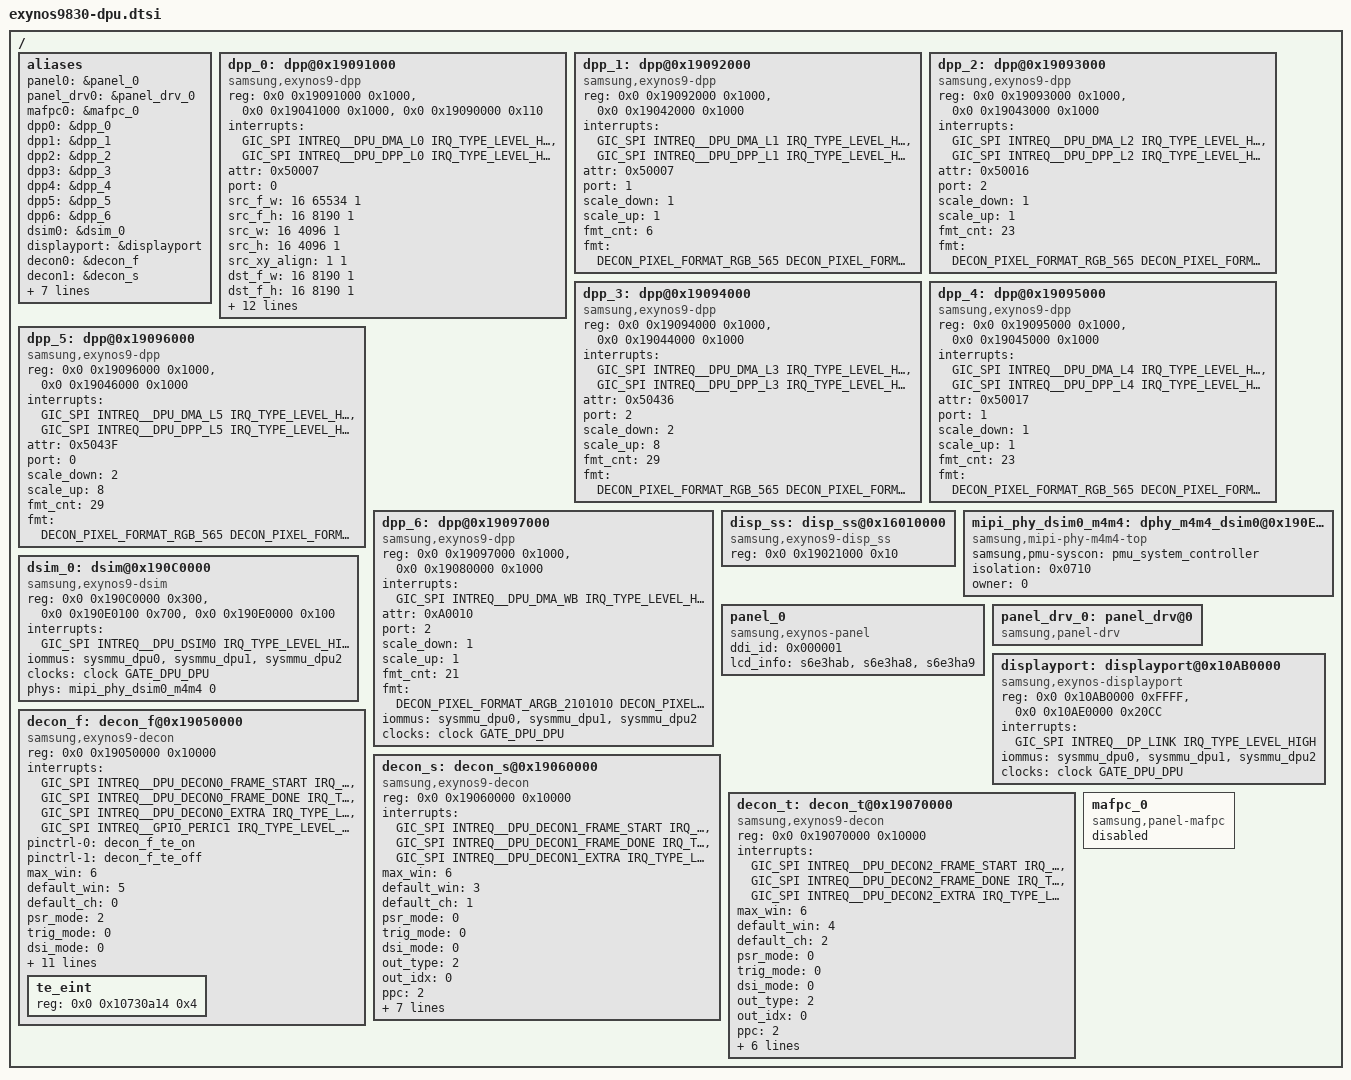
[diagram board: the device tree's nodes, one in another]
/*
 * SAMSUNG EXYNOS9830 SoC device tree source
 *
 * Copyright (c) 2014 Samsung Electronics Co., Ltd.
 *		http://www.samsung.com
 *
 * SAMSUNG EXYNOS9830 SoC device nodes are listed in this file.
 * EXYNOS based board files can include this file and provide
 * values for board specfic bindings.
 *
 * This program is free software; you can redistribute it and/or modify
 * it under the terms of the GNU General Public License version 2 as
 * published by the Free Software Foundation.
 */

#include <dt-bindings/interrupt-controller/arm-gic.h>
#include <dt-bindings/interrupt-controller/exynos9830.h>
#include <dt-bindings/display/exynos-display.h>
#include <dt-bindings/clock/exynos9830.h>
#include "exynos9830-display-lcd.dtsi"
#include "exynos9830-mcdhdr.dtsi"

/ {
	aliases {
		panel0 = &panel_0;
		panel_drv0 = &panel_drv_0;
       		mafpc0 = &mafpc_0;
		dpp0 = &dpp_0;
		dpp1 = &dpp_1;
		dpp2 = &dpp_2;
		dpp3 = &dpp_3;
		dpp4 = &dpp_4;
		dpp5 = &dpp_5;
		dpp6 = &dpp_6;
		dsim0 = &dsim_0;
		displayport = &displayport;
		decon0 = &decon_f;
		decon1 = &decon_s;
		decon2 = &decon_t;
		mcdhdr0 = &mcdhdr_0;
		mcdhdr1 = &mcdhdr_1;
		mcdhdr2 = &mcdhdr_2;
		mcdhdr3 = &mcdhdr_3;
		mcdhdr4 = &mcdhdr_4;
		mcdhdr5 = &mcdhdr_5;
	};

	dpp_0: dpp@0x19091000 {	/* GF0_L0 */
		compatible = "samsung,exynos9-dpp";
		#pb-id-cells = <3>;
		/* DPU_DMA, DPP, DPU_DMA_COMMON */
		reg = <0x0 0x19091000 0x1000>, <0x0 0x19041000 0x1000>, <0x0 0x19090000 0x110>;
		/* DPU_DMA IRQ, DPP IRQ */
		interrupts = <GIC_SPI INTREQ__DPU_DMA_L0 IRQ_TYPE_LEVEL_HIGH>,
			   <GIC_SPI INTREQ__DPU_DPP_L0 IRQ_TYPE_LEVEL_HIGH>;
		/* Each bit indicates DPP attribute */
		/* 0:AFBC 1:BLOCK 2:FLIP 3:ROT 4:CSC 5:SCALE 6:HDR 7:C_HDR 8:C_HDR10 9:WCG 10:SBWC */
		/* 16:IDMA 17:ODMA 18:DPP */
		/* DPP[18]/IDMA[16]/FLIP[2]/BLOCK[1]/AFBC[0] */
		attr = <0x50007>;
		port = <0>; /* AXI port number */

		/* HW restriction */
		src_f_w = <16 65534 1>;
		src_f_h = <16 8190 1>;
		src_w = <16 4096 1>;
		src_h = <16 4096 1>;
		src_xy_align = <1 1>;

		dst_f_w = <16 8190 1>;
		dst_f_h = <16 8190 1>;
		dst_w = <16 4096 1>;
		dst_h = <16 4096 1>;
		dst_xy_align = <1 1>;

		blk_w = <4 4096 1>;
		blk_h = <1 4096 1>;
		blk_xy_align = <1 1>;

		src_h_rot_max = <2160>;

		/* 1: scale X, 2: 1/2x scale down, 4: 1/4x scale down */
		scale_down = <1>;
		/* 1: scale X, 2: 2x scale up, 4: 4x scale up */
		scale_up = <1>;

		/* supported format count */
		fmt_cnt = <6>;
		/* supported format list */
		fmt = <DECON_PIXEL_FORMAT_RGB_565 DECON_PIXEL_FORMAT_BGR_565
			DECON_PIXEL_FORMAT_ARGB_2101010 DECON_PIXEL_FORMAT_ABGR_2101010
			DECON_PIXEL_FORMAT_RGBA_1010102 DECON_PIXEL_FORMAT_BGRA_1010102>;
	};

	dpp_1: dpp@0x19092000 {	/* GF1_L1 */
		compatible = "samsung,exynos9-dpp";
		#pb-id-cells = <3>;
		reg = <0x0 0x19092000 0x1000>, <0x0 0x19042000 0x1000>;
		interrupts = <GIC_SPI INTREQ__DPU_DMA_L1 IRQ_TYPE_LEVEL_HIGH>,
			   <GIC_SPI INTREQ__DPU_DPP_L1 IRQ_TYPE_LEVEL_HIGH>;
		/* DPP[18]/IDMA[16]/FLIP[2]/BLOCK[1]/AFBC[0] */
		attr = <0x50007>;
		port = <1>;
		scale_down = <1>;
		scale_up = <1>;
		fmt_cnt = <6>;
		fmt = <DECON_PIXEL_FORMAT_RGB_565 DECON_PIXEL_FORMAT_BGR_565
			DECON_PIXEL_FORMAT_ARGB_2101010 DECON_PIXEL_FORMAT_ABGR_2101010
			DECON_PIXEL_FORMAT_RGBA_1010102 DECON_PIXEL_FORMAT_BGRA_1010102>;
	};

	dpp_2: dpp@0x19093000 {	/* VG_L2 */
		compatible = "samsung,exynos9-dpp";
		#pb-id-cells = <3>;
		reg = <0x0 0x19093000 0x1000>, <0x0 0x19043000 0x1000>;
		interrupts = <GIC_SPI INTREQ__DPU_DMA_L2 IRQ_TYPE_LEVEL_HIGH>,
			   <GIC_SPI INTREQ__DPU_DPP_L2 IRQ_TYPE_LEVEL_HIGH>;
		/* DPP[18]/IDMA[16]/CSC[4]/FLIP[2]/BLOCK[1] */
		attr = <0x50016>;
		port = <2>;
		scale_down = <1>;
		scale_up = <1>;
		fmt_cnt = <23>;
		fmt = <DECON_PIXEL_FORMAT_RGB_565 DECON_PIXEL_FORMAT_BGR_565
			DECON_PIXEL_FORMAT_ARGB_2101010 DECON_PIXEL_FORMAT_ABGR_2101010
			DECON_PIXEL_FORMAT_RGBA_1010102 DECON_PIXEL_FORMAT_BGRA_1010102
			DECON_PIXEL_FORMAT_NV16 DECON_PIXEL_FORMAT_NV61
			DECON_PIXEL_FORMAT_NV12 DECON_PIXEL_FORMAT_NV21
			DECON_PIXEL_FORMAT_NV12M DECON_PIXEL_FORMAT_NV21M
			DECON_PIXEL_FORMAT_NV12N DECON_PIXEL_FORMAT_NV12N_10B
			DECON_PIXEL_FORMAT_NV12M_P010 DECON_PIXEL_FORMAT_NV21M_P010
			DECON_PIXEL_FORMAT_NV12M_S10B DECON_PIXEL_FORMAT_NV21M_S10B
			DECON_PIXEL_FORMAT_NV16M_P210 DECON_PIXEL_FORMAT_NV61M_P210
			DECON_PIXEL_FORMAT_NV16M_S10B DECON_PIXEL_FORMAT_NV61M_S10B
			DECON_PIXEL_FORMAT_NV12_P010>;
	};

	dpp_3: dpp@0x19094000 {	/* VGS_L3 */
		compatible = "samsung,exynos9-dpp";
		#pb-id-cells = <3>;
		reg = <0x0 0x19094000 0x1000>, <0x0 0x19044000 0x1000>;
		interrupts = <GIC_SPI INTREQ__DPU_DMA_L3 IRQ_TYPE_LEVEL_HIGH>,
			   <GIC_SPI INTREQ__DPU_DPP_L3 IRQ_TYPE_LEVEL_HIGH>;
		/* DPP[18]/IDMA[16]/SBWC[10]/SCALE[5]/CSC[4]/FLIP[2]/BLOCK[1] */
		attr = <0x50436>;
		port = <2>;
		scale_down = <2>;
		scale_up = <8>;
		fmt_cnt = <29>;
		fmt = <DECON_PIXEL_FORMAT_RGB_565 DECON_PIXEL_FORMAT_BGR_565
			DECON_PIXEL_FORMAT_ARGB_2101010 DECON_PIXEL_FORMAT_ABGR_2101010
			DECON_PIXEL_FORMAT_RGBA_1010102 DECON_PIXEL_FORMAT_BGRA_1010102
			DECON_PIXEL_FORMAT_NV16 DECON_PIXEL_FORMAT_NV61
			DECON_PIXEL_FORMAT_NV12 DECON_PIXEL_FORMAT_NV21
			DECON_PIXEL_FORMAT_NV12M DECON_PIXEL_FORMAT_NV21M
			DECON_PIXEL_FORMAT_NV12N DECON_PIXEL_FORMAT_NV12N_10B
			DECON_PIXEL_FORMAT_NV12M_P010 DECON_PIXEL_FORMAT_NV21M_P010
			DECON_PIXEL_FORMAT_NV12M_S10B DECON_PIXEL_FORMAT_NV21M_S10B
			DECON_PIXEL_FORMAT_NV16M_P210 DECON_PIXEL_FORMAT_NV61M_P210
			DECON_PIXEL_FORMAT_NV16M_S10B DECON_PIXEL_FORMAT_NV61M_S10B
			DECON_PIXEL_FORMAT_NV12_P010 DECON_PIXEL_FORMAT_NV12M_SBWC_8B
			DECON_PIXEL_FORMAT_NV12M_SBWC_10B DECON_PIXEL_FORMAT_NV21M_SBWC_8B
			DECON_PIXEL_FORMAT_NV21M_SBWC_10B DECON_PIXEL_FORMAT_NV12N_SBWC_8B
			DECON_PIXEL_FORMAT_NV12N_SBWC_10B>;
	};

	dpp_4: dpp@0x19095000 {	/* VGF_L4 */
		compatible = "samsung,exynos9-dpp";
		#pb-id-cells = <3>;
		reg = <0x0 0x19095000 0x1000>, <0x0 0x19045000 0x1000>;
		interrupts = <GIC_SPI INTREQ__DPU_DMA_L4 IRQ_TYPE_LEVEL_HIGH>,
			   <GIC_SPI INTREQ__DPU_DPP_L4 IRQ_TYPE_LEVEL_HIGH>;
		/* DPP[18]/IDMA[16]/CSC[4]/FLIP[2]/BLOCK[1]/AFBC[0] */
		attr = <0x50017>;
		port = <1>;
		scale_down = <1>;
		scale_up = <1>;
		fmt_cnt = <23>;
		fmt = <DECON_PIXEL_FORMAT_RGB_565 DECON_PIXEL_FORMAT_BGR_565
			DECON_PIXEL_FORMAT_ARGB_2101010 DECON_PIXEL_FORMAT_ABGR_2101010
			DECON_PIXEL_FORMAT_RGBA_1010102 DECON_PIXEL_FORMAT_BGRA_1010102
			DECON_PIXEL_FORMAT_NV16 DECON_PIXEL_FORMAT_NV61
			DECON_PIXEL_FORMAT_NV12 DECON_PIXEL_FORMAT_NV21
			DECON_PIXEL_FORMAT_NV12M DECON_PIXEL_FORMAT_NV21M
			DECON_PIXEL_FORMAT_NV12N DECON_PIXEL_FORMAT_NV12N_10B
			DECON_PIXEL_FORMAT_NV12M_P010 DECON_PIXEL_FORMAT_NV21M_P010
			DECON_PIXEL_FORMAT_NV12M_S10B DECON_PIXEL_FORMAT_NV21M_S10B
			DECON_PIXEL_FORMAT_NV16M_P210 DECON_PIXEL_FORMAT_NV61M_P210
			DECON_PIXEL_FORMAT_NV16M_S10B DECON_PIXEL_FORMAT_NV61M_S10B
			DECON_PIXEL_FORMAT_NV12_P010>;
	};

	dpp_5: dpp@0x19096000 {	/* VGRFS_L5 */
		compatible = "samsung,exynos9-dpp";
		#pb-id-cells = <3>;
		reg = <0x0 0x19096000 0x1000>, <0x0 0x19046000 0x1000>;
		interrupts = <GIC_SPI INTREQ__DPU_DMA_L5 IRQ_TYPE_LEVEL_HIGH>,
			   <GIC_SPI INTREQ__DPU_DPP_L5 IRQ_TYPE_LEVEL_HIGH>;
		/* DPP[18]/IDMA[16] */
		/* SBWC[10]/SCALE[5]/CSC[4]/ROT[3]/FLIP[2]/BLOCK[1]/AFBC[0] */
		attr = <0x5043F>;
		port = <0>;
		scale_down = <2>;
		scale_up = <8>;
		fmt_cnt = <29>;
		fmt = <DECON_PIXEL_FORMAT_RGB_565 DECON_PIXEL_FORMAT_BGR_565
			DECON_PIXEL_FORMAT_ARGB_2101010 DECON_PIXEL_FORMAT_ABGR_2101010
			DECON_PIXEL_FORMAT_RGBA_1010102 DECON_PIXEL_FORMAT_BGRA_1010102
			DECON_PIXEL_FORMAT_NV16 DECON_PIXEL_FORMAT_NV61
			DECON_PIXEL_FORMAT_NV12 DECON_PIXEL_FORMAT_NV21
			DECON_PIXEL_FORMAT_NV12M DECON_PIXEL_FORMAT_NV21M
			DECON_PIXEL_FORMAT_NV12N DECON_PIXEL_FORMAT_NV12N_10B
			DECON_PIXEL_FORMAT_NV12M_P010 DECON_PIXEL_FORMAT_NV21M_P010
			DECON_PIXEL_FORMAT_NV12M_S10B DECON_PIXEL_FORMAT_NV21M_S10B
			DECON_PIXEL_FORMAT_NV16M_P210 DECON_PIXEL_FORMAT_NV61M_P210
			DECON_PIXEL_FORMAT_NV16M_S10B DECON_PIXEL_FORMAT_NV61M_S10B
			DECON_PIXEL_FORMAT_NV12_P010 DECON_PIXEL_FORMAT_NV12M_SBWC_8B
			DECON_PIXEL_FORMAT_NV12M_SBWC_10B DECON_PIXEL_FORMAT_NV21M_SBWC_8B
			DECON_PIXEL_FORMAT_NV21M_SBWC_10B DECON_PIXEL_FORMAT_NV12N_SBWC_8B
			DECON_PIXEL_FORMAT_NV12N_SBWC_10B>;
	};

	dpp_6: dpp@0x19097000{
		compatible = "samsung,exynos9-dpp";
		#pb-id-cells = <3>;
		reg = <0x0 0x19097000 0x1000>, <0x0 0x19080000 0x1000>;
		interrupts = <GIC_SPI INTREQ__DPU_DMA_WB IRQ_TYPE_LEVEL_HIGH>;
		/* WBMUX[19]/ODMA[17]/CSC[4] */
		attr = <0xA0010>;
		port = <2>;
		scale_down = <1>;
		scale_up = <1>;
		fmt_cnt = <21>;
		fmt = <DECON_PIXEL_FORMAT_ARGB_2101010 DECON_PIXEL_FORMAT_ABGR_2101010
			DECON_PIXEL_FORMAT_RGBA_1010102 DECON_PIXEL_FORMAT_BGRA_1010102
			DECON_PIXEL_FORMAT_NV16 DECON_PIXEL_FORMAT_NV61
			DECON_PIXEL_FORMAT_NV12 DECON_PIXEL_FORMAT_NV21
			DECON_PIXEL_FORMAT_NV12M DECON_PIXEL_FORMAT_NV21M
			DECON_PIXEL_FORMAT_NV12N DECON_PIXEL_FORMAT_NV12N_10B
			DECON_PIXEL_FORMAT_NV12M_P010 DECON_PIXEL_FORMAT_NV21M_P010
			DECON_PIXEL_FORMAT_NV12M_S10B DECON_PIXEL_FORMAT_NV21M_S10B
			DECON_PIXEL_FORMAT_NV16M_P210 DECON_PIXEL_FORMAT_NV61M_P210
			DECON_PIXEL_FORMAT_NV16M_S10B DECON_PIXEL_FORMAT_NV61M_S10B
			DECON_PIXEL_FORMAT_NV12_P010>;

		/*
		 * dpp_6 is used for writeback. It means dpp_6 becomes
		 * output device of DECON. The output device has to manage
		 * power domain, clock and sysmmu control
		 */
		iommus = <&sysmmu_dpu0>, <&sysmmu_dpu1>, <&sysmmu_dpu2>;
		clock-names = "aclk";
		clocks = <&clock GATE_DPU_DPU>;
	};

	disp_ss: disp_ss@0x16010000 {
		compatible = "samsung,exynos9-disp_ss";
		reg = <0x0 0x19021000 0x10>;
	};

	mipi_phy_dsim0_m4m4: dphy_m4m4_dsim0@0x190E0000 {
		compatible = "samsung,mipi-phy-m4m4-top";
		samsung,pmu-syscon = <&pmu_system_controller>;
		isolation = <0x0710>;
		owner = <0>; /* 0: DSI_0 1: DSI_1 */
		#phy-cells = <1>;
	};

	dsim_0: dsim@0x190C0000 {
		compatible = "samsung,exynos9-dsim";
		/* DSIM0, DCPHY_M4M4_TOP, DCPHY_M4M4_COMMON */
		reg = <0x0 0x190C0000 0x300>, <0x0 0x190E0100 0x700>, <0x0 0x190E0000 0x100>;
		interrupts = <GIC_SPI INTREQ__DPU_DSIM0 IRQ_TYPE_LEVEL_HIGH>;
		iommus = <&sysmmu_dpu0>, <&sysmmu_dpu1>, <&sysmmu_dpu2>;

		/* clock */
		clock-names = "aclk";
		clocks = <&clock GATE_DPU_DPU>;

		 phys = <&mipi_phy_dsim0_m4m4 0>;
		 phy-names = "dsim_dphy";
	};

	panel_0: panel_0 {
		compatible = "samsung,exynos-panel";
		ddi_id = <0x000001>;
		lcd_info = <&s6e3hab>, <&s6e3ha8>, <&s6e3ha9>;
	};

	panel_drv_0: panel_drv@0 {
		compatible = "samsung,panel-drv";
	};

	displayport: displayport@0x10AB0000 {
		compatible = "samsung,exynos-displayport";
		reg = <0x0 0x10AB0000 0xFFFF>,
			<0x0 0x10AE0000 0x20CC>;
		interrupts = <GIC_SPI INTREQ__DP_LINK IRQ_TYPE_LEVEL_HIGH>;
		iommus = <&sysmmu_dpu0>, <&sysmmu_dpu1>, <&sysmmu_dpu2>;

		/* clock */
		clock-names = "aclk";
		clocks = <&clock GATE_DPU_DPU>;
	};

	decon_f: decon_f@0x19050000 {
		compatible = "samsung,exynos9-decon";
		#pb-id-cells = <4>;
		reg = <0x0 0x19050000 0x10000>;

		/* interrupt num : FRAME_START, FRMAE_DONE, EXTRA, GPIO_PERIC1(EXT_INT_TE: GPD0[0]) */
		interrupts = <GIC_SPI INTREQ__DPU_DECON0_FRAME_START IRQ_TYPE_LEVEL_HIGH>,
			     <GIC_SPI INTREQ__DPU_DECON0_FRAME_DONE IRQ_TYPE_LEVEL_HIGH>,
			     <GIC_SPI INTREQ__DPU_DECON0_EXTRA IRQ_TYPE_LEVEL_HIGH>,
			     <GIC_SPI INTREQ__GPIO_PERIC1 IRQ_TYPE_LEVEL_HIGH>;

		/* pinctrl */

		pinctrl-names = "hw_te_on", "hw_te_off";
		pinctrl-0 = <&decon_f_te_on>;
		pinctrl-1 = <&decon_f_te_off>;

		max_win = <6>;
		default_win = <5>;
		default_ch = <0>;
		psr_mode = <2>;         /* 0: video mode, 1: DP command mode, 2: MIPI command mode */
		trig_mode = <0>;        /* 0: hw trigger, 1: sw trigger */
		dsi_mode = <0>;         /* 0: single dsi, 1: dual dsi */

		/* 0: DSI, 1: eDP, 2:HDMI, 3: WB */
		out_type = <0>;
		/* 0: DSI0, 1: DSI1, 2: DSI2 */
		out_idx = <0>;

		/* pixel per clock */
		ppc = <2>;
		line_mem_cnt = <4>;
		cycle_per_line = <8>;   /* 4ppc */

		chip_ver = <9830>;

		dpp_cnt = <7>;
		dsim_cnt = <2>;
		decon_cnt = <3>;
		cursor_margin = <5>;

		#address-cells = <2>;
		#size-cells = <1>;
		ranges;

		/* EINT for TE */
		 gpios = <&gpc0 4 0xf>;
		/* sw te pending register */
		te_eint {
			/* NWEINT_GPC0_PEND */
			reg = <0x0 0x10730a14 0x4>;
		};
	};

	decon_s: decon_s@0x19060000 {
		compatible = "samsung,exynos9-decon";
		#pb-id-cells = <4>;
		reg = <0x0 0x19060000 0x10000>;

		/* interrupt num : FRAME_START, FRMAE_DONE, EXTRA */
		interrupts = <GIC_SPI INTREQ__DPU_DECON1_FRAME_START IRQ_TYPE_LEVEL_HIGH>,
			     <GIC_SPI INTREQ__DPU_DECON1_FRAME_DONE IRQ_TYPE_LEVEL_HIGH>,
			     <GIC_SPI INTREQ__DPU_DECON1_EXTRA IRQ_TYPE_LEVEL_HIGH>;

		max_win = <6>;
		default_win = <3>;
		default_ch = <1>;
		psr_mode = <0>;         /* 0: video mode, 1: DP command mode, 2: MIPI command mode */
		trig_mode = <0>;        /* 0: hw trigger, 1: sw trigger */
		dsi_mode = <0>;         /* 0: single dsi, 1: dual dsi */

		/* 0: DSI, 1: eDP, 2:DP */
		out_type = <2>;
		/* 0: DSI0, 1: DSI1, 2: DSI2 */
		out_idx = <0>;

		/* pixel per clock */
		ppc = <2>;
		line_mem_cnt = <4>;
		cycle_per_line = <8>;   /* 4ppc */

		chip_ver = <9830>;

		dpp_cnt = <7>;
		dsim_cnt = <2>;
		decon_cnt = <3>;
		cursor_margin = <40>;

		#address-cells = <2>;
		#size-cells = <1>;
		ranges;
	};

	decon_t: decon_t@0x19070000 {
		compatible = "samsung,exynos9-decon";
		#pb-id-cells = <4>;
		reg = <0x0 0x19070000 0x10000>;

		/* interrupt num : FRAME_START, FRMAE_DONE, EXTRA */
		interrupts = <GIC_SPI INTREQ__DPU_DECON2_FRAME_START IRQ_TYPE_LEVEL_HIGH>,
			     <GIC_SPI INTREQ__DPU_DECON2_FRAME_DONE IRQ_TYPE_LEVEL_HIGH>,
			     <GIC_SPI INTREQ__DPU_DECON2_EXTRA IRQ_TYPE_LEVEL_HIGH>;

		max_win = <6>;
		default_win = <4>;
		default_ch = <2>;
		psr_mode = <0>;         /* 0: video mode, 1: DP command mode, 2: MIPI command mode */
		trig_mode = <0>;        /* 0: hw trigger, 1: sw trigger */
		dsi_mode = <0>;         /* 0: single dsi, 1: dual dsi */

		/* 0: DSI, 1: eDP, 2:DP */
		out_type = <2>;
		/* 0: DSI0, 1: DSI1, 2: DSI2 */
		out_idx = <0>;

		/* pixel per clock */
		ppc = <2>;
		line_mem_cnt = <4>;
		cycle_per_line = <8>;   /* 4ppc */

		chip_ver = <9830>;

		dpp_cnt = <7>;
		dsim_cnt = <2>;
		decon_cnt = <3>;

		#address-cells = <2>;
		#size-cells = <1>;
		ranges;
	};

	mafpc_0: mafpc_0 {
		compatible = "samsung,panel-mafpc";
		status = "disabled";
	};
};
